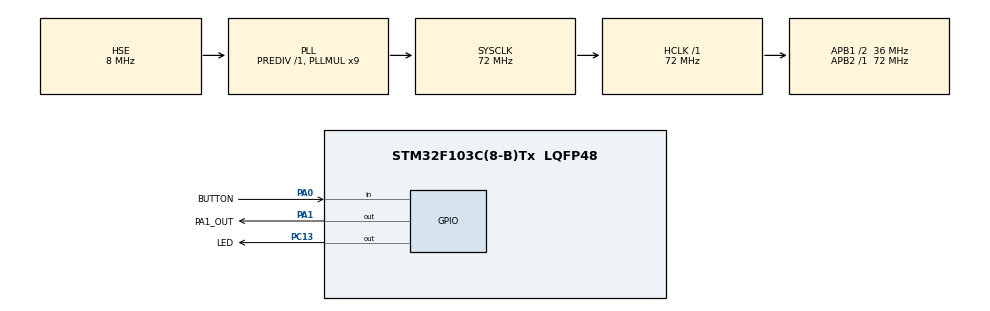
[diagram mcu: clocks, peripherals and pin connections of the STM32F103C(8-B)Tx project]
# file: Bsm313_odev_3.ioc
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Mcu.Family=STM32F1
Mcu.Name=STM32F103C(8-B)Tx
Mcu.Package=LQFP48
NVIC.PriorityGroup=NVIC_PRIORITYGROUP_4
NVIC.TIM2_IRQn=true\:0\:0\:false\:false\:true\:true\:true\:true
PA0-WKUP.GPIO_Label=BUTTON
PA0-WKUP.GPIO_PuPd=GPIO_PULLUP
PA0-WKUP.Signal=GPIO_Input
PA1.GPIO_Label=PA1_OUT
PA1.Signal=GPIO_Output
PA13.Mode=Serial_Wire
PA13.Signal=SYS_JTMS-SWDIO
PA14.Mode=Serial_Wire
PA14.Signal=SYS_JTCK-SWCLK
PC13-TAMPER-RTC.GPIO_Label=LED
PC13-TAMPER-RTC.Signal=GPIO_Output
PD0-OSC_IN.Mode=HSE-External-Oscillator
PD0-OSC_IN.Signal=RCC_OSC_IN
PD1-OSC_OUT.Mode=HSE-External-Oscillator
PD1-OSC_OUT.Signal=RCC_OSC_OUT
ProjectManager.HeapSize=0x200
ProjectManager.StackSize=0x400
ProjectManager.TargetToolchain=STM32CubeIDE
RCC.AHBFreq_Value=72000000
RCC.APB1CLKDivider=RCC_HCLK_DIV2
RCC.APB1Freq_Value=36000000
RCC.APB1TimFreq_Value=72000000
RCC.APB2Freq_Value=72000000
RCC.APB2TimFreq_Value=72000000
RCC.HCLKFreq_Value=72000000
RCC.PLLMUL=RCC_PLL_MUL9
RCC.PLLSourceVirtual=RCC_PLLSOURCE_HSE
RCC.SYSCLKFreq_VALUE=72000000
RCC.SYSCLKSource=RCC_SYSCLKSOURCE_PLLCLK
RCC.USBFreq_Value=72000000
TIM2.AutoReloadPreload=TIM_AUTORELOAD_PRELOAD_ENABLE
TIM2.Period=9999
TIM2.Prescaler=7199
VP_TIM2_VS_ClockSourceINT.Mode=Internal
board=custom

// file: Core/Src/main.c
/* USER CODE BEGIN Header */
/**
  ******************************************************************************
  * @file           : main.c
  * @brief          : Main program body
  ******************************************************************************
  */
/* USER CODE END Header */
#include "main.h"

TIM_HandleTypeDef htim2;

/* USER CODE BEGIN PV */
#define FLASH_USER_ADDR  0x0800FC00

volatile uint8_t blink_count = 4;
volatile uint8_t blink_tick = 0;
volatile uint8_t wait_tick = 0;
volatile uint8_t led_state = 0;   // 0: sönük, 1: yanık
volatile uint8_t state = 0;       // 0: blink fazı, 1: 5sn bekleme

volatile uint8_t flash_write_req = 0;
volatile uint8_t flash_write_val = 0;

uint8_t btn_prev = GPIO_PIN_SET;  // Butonun bir önceki durumu
/* USER CODE END PV */

void SystemClock_Config(void);
static void MX_GPIO_Init(void);
static void MX_TIM2_Init(void);

int main(void)
{

  /* MCU Configuration--------------------------------------------------------*/

  /* Reset of all peripherals, Initializes the Flash interface and the Systick. */
  HAL_Init();

  /* Configure the system clock */
  SystemClock_Config();

  /* Initialize all configured peripherals */
  MX_GPIO_Init();
  MX_TIM2_Init();
  /* USER CODE BEGIN 2 */

  // Flash'tan son kayıtlı değeri oku
  uint32_t flash_val = *(__IO uint32_t*)FLASH_USER_ADDR;

  // Boşsa (0xFFFFFFFF) veya 4-7 aralığı dışındaysa -> 4 yap
  if(flash_val == 0xFFFFFFFF || flash_val < 4 || flash_val > 7) {
      blink_count = 4;
  } else {
      blink_count = (uint8_t)flash_val;
  }

  // --- AÇILISTA FABRİKA AYARLARI KONTROLÜ (Adım: g) ---
  // Güç verilir verilmez butona basılıysa ve 3sn bırakılmazsa 4'e sıfırla
  if (HAL_GPIO_ReadPin(BUTTON_GPIO_Port, BUTTON_Pin) == GPIO_PIN_RESET) {
      uint32_t boot_press_start = HAL_GetTick();
      uint8_t factory_reset_triggered = 0;

      // Buton basılı olduğu sürece bekle
      while (HAL_GPIO_ReadPin(BUTTON_GPIO_Port, BUTTON_Pin) == GPIO_PIN_RESET) {
          if (HAL_GetTick() - boot_press_start >= 3000) { // 3 saniye doldu mu?
              factory_reset_triggered = 1;
              break;
          }
      }

      // Eğer 3 saniye kesintisiz basıldıysa sıfırla
      if (factory_reset_triggered) {
          blink_count = 4;
          flash_write_val = 4;
          flash_write_req = 1;

          // Buton bırakılana kadar burada bekle ki normal döngüye geçince
          // ekstra bir kısa basış algılamasın
          while(HAL_GPIO_ReadPin(BUTTON_GPIO_Port, BUTTON_Pin) == GPIO_PIN_RESET) {
              HAL_Delay(10);
          }
      }
  }

  // LED başlangıçta SÖNÜK (PC13 active-low)
  HAL_GPIO_WritePin(LED_GPIO_Port, LED_Pin, GPIO_PIN_SET);
  // PA1 = Lojik 0
  HAL_GPIO_WritePin(PA1_OUT_GPIO_Port, PA1_OUT_Pin, GPIO_PIN_RESET);

  // TIM2 interrupt'ını başlat (SANİYEDE 1 KERE)
  HAL_TIM_Base_Start_IT(&htim2);

  /* USER CODE END 2 */

  /* Infinite loop */
  while (1)
  {

    /* USER CODE BEGIN 3 */

    // --- FLASH YAZMA İSLLEMİ ---
    if(flash_write_req) {
        flash_write_req = 0;

        HAL_FLASH_Unlock();

        FLASH_EraseInitTypeDef erase;
        erase.TypeErase = FLASH_TYPEERASE_PAGES;
        erase.PageAddress = FLASH_USER_ADDR;
        erase.NbPages = 1;
        uint32_t page_error = 0;
        HAL_FLASHEx_Erase(&erase, &page_error);

        HAL_FLASH_Program(FLASH_TYPEPROGRAM_WORD, FLASH_USER_ADDR, (uint32_t)flash_write_val);

        HAL_FLASH_Lock();
    }

    uint8_t btn_now = HAL_GPIO_ReadPin(BUTTON_GPIO_Port, BUTTON_Pin);

    if (btn_now == GPIO_PIN_RESET && btn_prev == GPIO_PIN_SET) {
        // Butona basıldı
        btn_prev = GPIO_PIN_RESET;
        HAL_Delay(50);
    }
    else if (btn_now == GPIO_PIN_SET && btn_prev == GPIO_PIN_RESET) {
        // Buton bırakıldı
        btn_prev = GPIO_PIN_SET;

        blink_count++;
        if(blink_count > 7) {
            blink_count = 4;
        }
        flash_write_val = blink_count;
        flash_write_req = 1;

        // Timer ve durumu sıfırla ki yeni blink animasyonu
        HAL_TIM_Base_Stop_IT(&htim2);
        state = 0;
        blink_tick = 0;
        wait_tick = 0;
        led_state = 0;
        HAL_GPIO_WritePin(LED_GPIO_Port, LED_Pin, GPIO_PIN_SET);
        __HAL_TIM_SET_COUNTER(&htim2, 0);
        HAL_TIM_Base_Start_IT(&htim2);

        HAL_Delay(50); // Titreşim  engelleme
    }

    HAL_Delay(10);
  }
  /* USER CODE END 3 */
}

void SystemClock_Config(void)
{
  RCC_OscInitTypeDef RCC_OscInitStruct = {0};
  RCC_ClkInitTypeDef RCC_ClkInitStruct = {0};

  /** Initializes the RCC Oscillators according to the specified parameters
  * in the RCC_OscInitTypeDef structure.
  */
  RCC_OscInitStruct.OscillatorType = RCC_OSCILLATORTYPE_HSE;
  RCC_OscInitStruct.HSEState = RCC_HSE_ON;
  RCC_OscInitStruct.HSEPredivValue = RCC_HSE_PREDIV_DIV1;
  RCC_OscInitStruct.HSIState = RCC_HSI_ON;
  RCC_OscInitStruct.PLL.PLLState = RCC_PLL_ON;
  RCC_OscInitStruct.PLL.PLLSource = RCC_PLLSOURCE_HSE;
  RCC_OscInitStruct.PLL.PLLMUL = RCC_PLL_MUL9;
  if (HAL_RCC_OscConfig(&RCC_OscInitStruct) != HAL_OK)
  {
    Error_Handler();
  }

  /** Initializes the CPU, AHB and APB buses clocks
  */
  RCC_ClkInitStruct.ClockType = RCC_CLOCKTYPE_HCLK|RCC_CLOCKTYPE_SYSCLK
                              |RCC_CLOCKTYPE_PCLK1|RCC_CLOCKTYPE_PCLK2;
  RCC_ClkInitStruct.SYSCLKSource = RCC_SYSCLKSOURCE_PLLCLK;
  RCC_ClkInitStruct.AHBCLKDivider = RCC_SYSCLK_DIV1;
  RCC_ClkInitStruct.APB1CLKDivider = RCC_HCLK_DIV2;
  RCC_ClkInitStruct.APB2CLKDivider = RCC_HCLK_DIV1;

  if (HAL_RCC_ClockConfig(&RCC_ClkInitStruct, FLASH_LATENCY_2) != HAL_OK)
  {
    Error_Handler();
  }
}

static void MX_TIM2_Init(void)
{

  TIM_ClockConfigTypeDef sClockSourceConfig = {0};
  TIM_MasterConfigTypeDef sMasterConfig = {0};

  htim2.Instance = TIM2;
  htim2.Init.Prescaler = 7199;
  htim2.Init.CounterMode = TIM_COUNTERMODE_UP;
  htim2.Init.Period = 9999;
  htim2.Init.ClockDivision = TIM_CLOCKDIVISION_DIV1;
  htim2.Init.AutoReloadPreload = TIM_AUTORELOAD_PRELOAD_ENABLE;
  if (HAL_TIM_Base_Init(&htim2) != HAL_OK)
  {
    Error_Handler();
  }
  sClockSourceConfig.ClockSource = TIM_CLOCKSOURCE_INTERNAL;
  if (HAL_TIM_ConfigClockSource(&htim2, &sClockSourceConfig) != HAL_OK)
  {
    Error_Handler();
  }
  sMasterConfig.MasterOutputTrigger = TIM_TRGO_RESET;
  sMasterConfig.MasterSlaveMode = TIM_MASTERSLAVEMODE_DISABLE;
  if (HAL_TIMEx_MasterConfigSynchronization(&htim2, &sMasterConfig) != HAL_OK)
  {
    Error_Handler();
  }

}

static void MX_GPIO_Init(void)
{
  GPIO_InitTypeDef GPIO_InitStruct = {0};

  /* GPIO Ports Clock Enable */
  __HAL_RCC_GPIOC_CLK_ENABLE();
  __HAL_RCC_GPIOD_CLK_ENABLE();
  __HAL_RCC_GPIOA_CLK_ENABLE();

  /*Configure GPIO pin Output Level */
  HAL_GPIO_WritePin(LED_GPIO_Port, LED_Pin, GPIO_PIN_RESET);

  /*Configure GPIO pin Output Level */
  HAL_GPIO_WritePin(PA1_OUT_GPIO_Port, PA1_OUT_Pin, GPIO_PIN_RESET);

  /*Configure GPIO pin : LED_Pin */
  GPIO_InitStruct.Pin = LED_Pin;
  GPIO_InitStruct.Mode = GPIO_MODE_OUTPUT_PP;
  GPIO_InitStruct.Pull = GPIO_NOPULL;
  GPIO_InitStruct.Speed = GPIO_SPEED_FREQ_LOW;
  HAL_GPIO_Init(LED_GPIO_Port, &GPIO_InitStruct);

  /*Configure GPIO pin : BUTTON_Pin */
  GPIO_InitStruct.Pin = BUTTON_Pin;
  GPIO_InitStruct.Mode = GPIO_MODE_INPUT;
  GPIO_InitStruct.Pull = GPIO_PULLUP;
  HAL_GPIO_Init(BUTTON_GPIO_Port, &GPIO_InitStruct);

  /*Configure GPIO pin : PA1_OUT_Pin */
  GPIO_InitStruct.Pin = PA1_OUT_Pin;
  GPIO_InitStruct.Mode = GPIO_MODE_OUTPUT_PP;
  GPIO_InitStruct.Pull = GPIO_NOPULL;
  GPIO_InitStruct.Speed = GPIO_SPEED_FREQ_LOW;
  HAL_GPIO_Init(PA1_OUT_GPIO_Port, &GPIO_InitStruct);

}

/* USER CODE BEGIN 4 */
void HAL_TIM_PeriodElapsedCallback(TIM_HandleTypeDef *htim)
{
    if(htim->Instance != TIM2) return;

    // ===== LED KONTROLÜ (PC13 - Active-Low) =====
    if(state == 0) {
        // BLINK FAZI: Her saniye toggle (ters çevir)
        led_state = !led_state;
        HAL_GPIO_WritePin(LED_GPIO_Port, LED_Pin, led_state ? GPIO_PIN_RESET : GPIO_PIN_SET);
        blink_tick++;

        if(blink_tick >= (blink_count * 2)) {
            blink_tick = 0;
            state = 1;              // 5sn bekleme fazı
            led_state = 0;
            HAL_GPIO_WritePin(LED_GPIO_Port, LED_Pin, GPIO_PIN_SET); //sönük
        }
    }
    else if(state == 1) {
        // 5 SANİYE BEKLEME FAZI
        wait_tick++;
        if(wait_tick >= 5) {
            wait_tick = 0;
            state = 0;              // Tekrar blink fazı
        }
    }
}
/* USER CODE END 4 */

void Error_Handler(void)
{
  __disable_irq();
  while (1)
  {
  }
}
